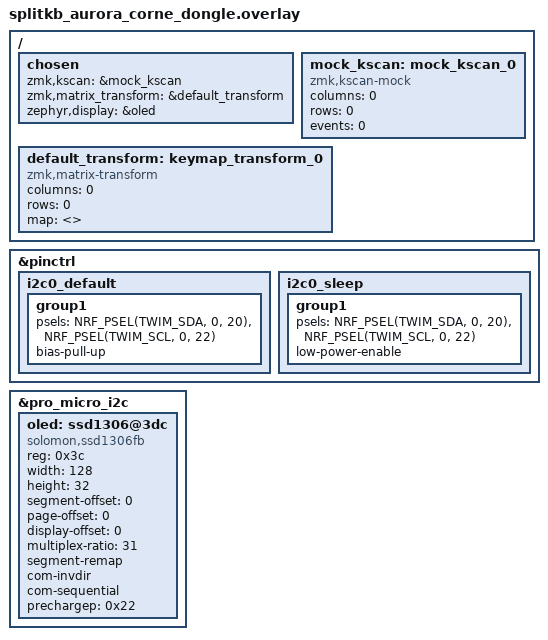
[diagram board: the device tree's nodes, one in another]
#include <dt-bindings/zmk/matrix_transform.h>

/ {
    chosen {
        zmk,kscan = &mock_kscan;
        zmk,matrix_transform = &default_transform;
        zephyr,display = &oled;
    };

    mock_kscan: mock_kscan_0 {
        compatible = "zmk,kscan-mock";
        columns = <0>;
        rows = <0>;
        events = <0>;
    };

    default_transform: keymap_transform_0 {
        compatible = "zmk,matrix-transform";
        columns = <0>;
        rows = <0>;
        map = <>;
    };
};

&pinctrl {
    i2c0_default: i2c0_default {
        group1 {
            // Sintaxis: NRF_PSEL(FUNCIÓN, PUERTO, PIN)
            // SDA -> Puerto 0, Pin 20 (Según tu cableado)
            // SCL -> Puerto 0, Pin 22 (Según tu cableado)
            psels = <NRF_PSEL(TWIM_SDA, 0, 20)>,
                    <NRF_PSEL(TWIM_SCL, 0, 22)>;
            bias-pull-up; // Resistencias pull-up internas (ayudan si el módulo no las tiene)
        };
    };

    i2c0_sleep: i2c0_sleep {
        group1 {
            psels = <NRF_PSEL(TWIM_SDA, 0, 20)>,
                    <NRF_PSEL(TWIM_SCL, 0, 22)>;
            low-power-enable;
        };
    };
};

&pro_micro_i2c {
    status = "okay";

    oled: ssd1306@3dc {
        compatible = "solomon,ssd1306fb";
        reg = <0x3c>; // Dirección I2C (casi siempre es 3c o 3d)
        width = <128>;
        height = <32>;
        segment-offset = <0>;
        page-offset = <0>;
        display-offset = <0>;
        multiplex-ratio = <31>;
        segment-remap;
        com-invdir;
        com-sequential;
        prechargep = <0x22>;
    };
};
